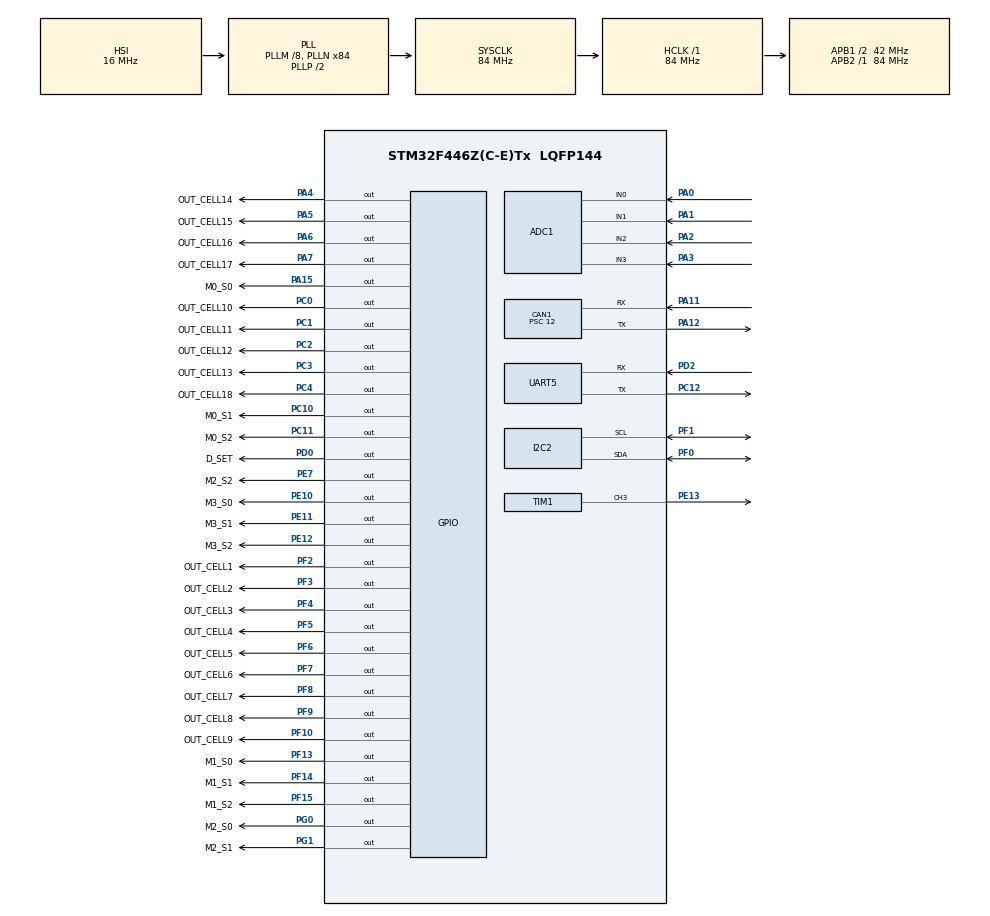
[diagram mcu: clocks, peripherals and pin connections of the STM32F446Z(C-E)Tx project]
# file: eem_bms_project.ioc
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ADC1.Channel-0\#ChannelRegularConversion=ADC_CHANNEL_0
ADC1.Channel-1\#ChannelRegularConversion=ADC_CHANNEL_1
ADC1.Channel-2\#ChannelRegularConversion=ADC_CHANNEL_2
ADC1.Channel-3\#ChannelRegularConversion=ADC_CHANNEL_3
ADC1.Channel-5\#ChannelRegularConversion=ADC_CHANNEL_VBAT
ADC1.Channel-6\#ChannelRegularConversion=ADC_CHANNEL_VREFINT
ADC1.ContinuousConvMode=ENABLE
ADC1.NbrOfConversion=6
ADC1.NbrOfConversionFlag=1
ADC1.Rank-0\#ChannelRegularConversion=1
ADC1.Rank-1\#ChannelRegularConversion=2
ADC1.Rank-2\#ChannelRegularConversion=3
ADC1.Rank-3\#ChannelRegularConversion=4
ADC1.Rank-5\#ChannelRegularConversion=5
ADC1.Rank-6\#ChannelRegularConversion=6
ADC1.SamplingTime-0\#ChannelRegularConversion=ADC_SAMPLETIME_480CYCLES
ADC1.SamplingTime-1\#ChannelRegularConversion=ADC_SAMPLETIME_480CYCLES
ADC1.SamplingTime-2\#ChannelRegularConversion=ADC_SAMPLETIME_480CYCLES
ADC1.SamplingTime-3\#ChannelRegularConversion=ADC_SAMPLETIME_480CYCLES
ADC1.SamplingTime-5\#ChannelRegularConversion=ADC_SAMPLETIME_28CYCLES
ADC1.SamplingTime-6\#ChannelRegularConversion=ADC_SAMPLETIME_28CYCLES
ADC1.ScanConvMode=ENABLE
ADC1.master=1
CAN1.BS1=CAN_BS1_11TQ
CAN1.BS2=CAN_BS2_2TQ
CAN1.CalculateBaudRate=250000
CAN1.CalculateTimeBit=4000
CAN1.CalculateTimeQuantum=285.7142857142857
CAN1.NART=ENABLE
CAN1.Prescaler=12
Mcu.Family=STM32F4
Mcu.Name=STM32F446Z(C-E)Tx
Mcu.Package=LQFP144
NVIC.CAN1_RX0_IRQn=true\:0\:0\:false\:false\:true\:true\:true\:true
NVIC.CAN1_RX1_IRQn=true\:0\:0\:false\:false\:true\:true\:true\:true
NVIC.CAN1_SCE_IRQn=true\:0\:0\:false\:false\:true\:true\:true\:true
NVIC.CAN1_TX_IRQn=true\:0\:0\:false\:false\:true\:true\:true\:true
NVIC.PriorityGroup=NVIC_PRIORITYGROUP_4
PA0-WKUP.Signal=ADCx_IN0
PA1.Signal=ADCx_IN1
PA11.Mode=CAN_Activate
PA11.Signal=CAN1_RX
PA12.Mode=CAN_Activate
PA12.Signal=CAN1_TX
PA13.Mode=Serial_Wire
PA13.Signal=SYS_JTMS-SWDIO
PA14.Mode=Serial_Wire
PA14.Signal=SYS_JTCK-SWCLK
PA15.GPIO_Label=M0_S0
PA15.Signal=GPIO_Output
PA2.Signal=ADCx_IN2
PA3.Signal=ADCx_IN3
PA4.GPIO_Label=OUT_CELL14
PA4.Signal=GPIO_Output
PA5.GPIO_Label=OUT_CELL15
PA5.Signal=GPIO_Output
PA6.GPIO_Label=OUT_CELL16
PA6.Signal=GPIO_Output
PA7.GPIO_Label=OUT_CELL17
PA7.Signal=GPIO_Output
PC0.GPIO_Label=OUT_CELL10
PC0.Signal=GPIO_Output
PC1.GPIO_Label=OUT_CELL11
PC1.Signal=GPIO_Output
PC10.GPIO_Label=M0_S1
PC10.Signal=GPIO_Output
PC11.GPIO_Label=M0_S2
PC11.Signal=GPIO_Output
PC12.Mode=Asynchronous
PC12.Signal=UART5_TX
PC2.GPIO_Label=OUT_CELL12
PC2.Signal=GPIO_Output
PC3.GPIO_Label=OUT_CELL13
PC3.Signal=GPIO_Output
PC4.GPIO_Label=OUT_CELL18
PC4.Signal=GPIO_Output
PD0.GPIO_Label=D_SET
PD0.Signal=GPIO_Output
PD2.Mode=Asynchronous
PD2.Signal=UART5_RX
PE10.GPIO_Label=M3_S0
PE10.Signal=GPIO_Output
PE11.GPIO_Label=M3_S1
PE11.Signal=GPIO_Output
PE12.GPIO_Label=M3_S2
PE12.Signal=GPIO_Output
PE13.Signal=S_TIM1_CH3
PE7.GPIO_Label=M2_S2
PE7.Signal=GPIO_Output
PF0.Mode=I2C
PF0.Signal=I2C2_SDA
PF1.Mode=I2C
PF1.Signal=I2C2_SCL
PF10.GPIO_Label=OUT_CELL9
PF10.Signal=GPIO_Output
PF13.GPIO_Label=M1_S0
PF13.Signal=GPIO_Output
PF14.GPIO_Label=M1_S1
PF14.Signal=GPIO_Output
PF15.GPIO_Label=M1_S2
PF15.Signal=GPIO_Output
PF2.GPIO_Label=OUT_CELL1
PF2.Signal=GPIO_Output
PF3.GPIO_Label=OUT_CELL2
PF3.Signal=GPIO_Output
PF4.GPIO_Label=OUT_CELL3
PF4.Signal=GPIO_Output
PF5.GPIO_Label=OUT_CELL4
PF5.Signal=GPIO_Output
PF6.GPIO_Label=OUT_CELL5
PF6.Signal=GPIO_Output
PF7.GPIO_Label=OUT_CELL6
PF7.Signal=GPIO_Output
PF8.GPIO_Label=OUT_CELL7
PF8.Signal=GPIO_Output
PF9.GPIO_Label=OUT_CELL8
PF9.Signal=GPIO_Output
PG0.GPIO_Label=M2_S0
PG0.Signal=GPIO_Output
PG1.GPIO_Label=M2_S1
PG1.Signal=GPIO_Output
PH0-OSC_IN.Mode=HSE-External-Oscillator
PH0-OSC_IN.Signal=RCC_OSC_IN
PH1-OSC_OUT.Mode=HSE-External-Oscillator
PH1-OSC_OUT.Signal=RCC_OSC_OUT
ProjectManager.HeapSize=0x200
ProjectManager.StackSize=0x400
ProjectManager.TargetToolchain=STM32CubeIDE
RCC.AHBFreq_Value=84000000
RCC.APB1CLKDivider=RCC_HCLK_DIV2
RCC.APB1Freq_Value=42000000
RCC.APB1TimFreq_Value=84000000
RCC.APB2Freq_Value=84000000
RCC.APB2TimFreq_Value=84000000
RCC.CortexFreq_Value=84000000
RCC.HCLKFreq_Value=84000000
RCC.PLLM=8
RCC.PLLN=84
RCC.SYSCLKFreq_VALUE=84000000
RCC.SYSCLKSource=RCC_SYSCLKSOURCE_PLLCLK
RCC.USBFreq_Value=84000000
RCC.VCOOutputFreq_Value=168000000
SH.ADCx_IN0.0=ADC1_IN0,IN0
SH.ADCx_IN1.0=ADC1_IN1,IN1
SH.ADCx_IN2.0=ADC1_IN2,IN2
SH.ADCx_IN3.0=ADC1_IN3,IN3
SH.S_TIM1_CH3.0=TIM1_CH3,Output Compare3 CH3
TIM1.Channel-Output\ Compare3\ CH3=TIM_CHANNEL_3
TIM1.Period=8399
TIM1.Prescaler=5
UART5.VirtualMode=Asynchronous
VP_ADC1_Vbat_Input.Mode=IN-Vbat
VP_ADC1_Vref_Input.Mode=IN-Vrefint
VP_RTC_VS_RTC_Activate.Mode=RTC_Enabled
VP_TIM1_VS_ClockSourceINT.Mode=Internal
board=custom

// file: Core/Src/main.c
/* USER CODE BEGIN Header */
/**
  ******************************************************************************
  * @file           : main.c
  * @brief          : Main program body
  ******************************************************************************
  * @attention
  *
  * Copyright (c) 2023 STMicroelectronics.
  * All rights reserved.
  *
  * This software is licensed under terms that can be found in the LICENSE file
  * in the root directory of this software component.
  * If no LICENSE file comes with this software, it is provided AS-IS.
  *
  ******************************************************************************
  */
/* USER CODE END Header */
#include "main.h"

ADC_HandleTypeDef hadc1;

CAN_HandleTypeDef hcan1;

I2C_HandleTypeDef hi2c2;

RTC_HandleTypeDef hrtc;

TIM_HandleTypeDef htim1;

UART_HandleTypeDef huart5;

void SystemClock_Config(void);
static void MX_GPIO_Init(void);
static void MX_ADC1_Init(void);
static void MX_CAN1_Init(void);
static void MX_I2C2_Init(void);
static void MX_RTC_Init(void);
static void MX_TIM1_Init(void);
static void MX_UART5_Init(void);

int main(void)
{

  /* MCU Configuration--------------------------------------------------------*/

  /* Reset of all peripherals, Initializes the Flash interface and the Systick. */
  HAL_Init();

  /* Configure the system clock */
  SystemClock_Config();

  /* Initialize all configured peripherals */
  MX_GPIO_Init();
  MX_ADC1_Init();
  MX_CAN1_Init();
  MX_I2C2_Init();
  MX_RTC_Init();
  MX_TIM1_Init();
  MX_UART5_Init();
  /* USER CODE BEGIN 2 */

  /* JUMP INTO MAIN BMS CODE */
  App_MAIN();

  /* USER CODE END 2 */

  /* Infinite loop */
  while (1)
  {

  }
}

void SystemClock_Config(void)
{
  RCC_OscInitTypeDef RCC_OscInitStruct = {0};
  RCC_ClkInitTypeDef RCC_ClkInitStruct = {0};

  /** Configure the main internal regulator output voltage
  */
  __HAL_RCC_PWR_CLK_ENABLE();
  __HAL_PWR_VOLTAGESCALING_CONFIG(PWR_REGULATOR_VOLTAGE_SCALE3);

  /** Initializes the RCC Oscillators according to the specified parameters
  * in the RCC_OscInitTypeDef structure.
  */
  RCC_OscInitStruct.OscillatorType = RCC_OSCILLATORTYPE_HSI|RCC_OSCILLATORTYPE_LSI;
  RCC_OscInitStruct.LSEState = RCC_LSE_OFF;
  RCC_OscInitStruct.HSIState = RCC_HSI_ON;
  RCC_OscInitStruct.HSICalibrationValue = RCC_HSICALIBRATION_DEFAULT;
  RCC_OscInitStruct.LSIState = RCC_LSI_ON;
  RCC_OscInitStruct.PLL.PLLState = RCC_PLL_ON;
  RCC_OscInitStruct.PLL.PLLSource = RCC_PLLSOURCE_HSI;
  RCC_OscInitStruct.PLL.PLLM = 8;
  RCC_OscInitStruct.PLL.PLLN = 84;
  RCC_OscInitStruct.PLL.PLLP = RCC_PLLP_DIV2;
  RCC_OscInitStruct.PLL.PLLQ = 2;
  RCC_OscInitStruct.PLL.PLLR = 2;
  if (HAL_RCC_OscConfig(&RCC_OscInitStruct) != HAL_OK)
  {
    Error_Handler();
  }

  /** Initializes the CPU, AHB and APB buses clocks
  */
  RCC_ClkInitStruct.ClockType = RCC_CLOCKTYPE_HCLK|RCC_CLOCKTYPE_SYSCLK
                              |RCC_CLOCKTYPE_PCLK1|RCC_CLOCKTYPE_PCLK2;
  RCC_ClkInitStruct.SYSCLKSource = RCC_SYSCLKSOURCE_PLLCLK;
  RCC_ClkInitStruct.AHBCLKDivider = RCC_SYSCLK_DIV1;
  RCC_ClkInitStruct.APB1CLKDivider = RCC_HCLK_DIV2;
  RCC_ClkInitStruct.APB2CLKDivider = RCC_HCLK_DIV1;

  if (HAL_RCC_ClockConfig(&RCC_ClkInitStruct, FLASH_LATENCY_2) != HAL_OK)
  {
    Error_Handler();
  }
}

static void MX_ADC1_Init(void)
{

  ADC_ChannelConfTypeDef sConfig = {0};

  /** Configure the global features of the ADC (Clock, Resolution, Data Alignment and number of conversion)
  */
  hadc1.Instance = ADC1;
  hadc1.Init.ClockPrescaler = ADC_CLOCK_SYNC_PCLK_DIV4;
  hadc1.Init.Resolution = ADC_RESOLUTION_12B;
  hadc1.Init.ScanConvMode = ENABLE;
  hadc1.Init.ContinuousConvMode = ENABLE;
  hadc1.Init.DiscontinuousConvMode = DISABLE;
  hadc1.Init.ExternalTrigConvEdge = ADC_EXTERNALTRIGCONVEDGE_NONE;
  hadc1.Init.ExternalTrigConv = ADC_SOFTWARE_START;
  hadc1.Init.DataAlign = ADC_DATAALIGN_RIGHT;
  hadc1.Init.NbrOfConversion = 6;
  hadc1.Init.DMAContinuousRequests = DISABLE;
  hadc1.Init.EOCSelection = ADC_EOC_SINGLE_CONV;
  if (HAL_ADC_Init(&hadc1) != HAL_OK)
  {
    Error_Handler();
  }

  /** Configure for the selected ADC regular channel its corresponding rank in the sequencer and its sample time.
  */
  sConfig.Channel = ADC_CHANNEL_0;
  sConfig.Rank = 1;
  sConfig.SamplingTime = ADC_SAMPLETIME_480CYCLES;
  if (HAL_ADC_ConfigChannel(&hadc1, &sConfig) != HAL_OK)
  {
    Error_Handler();
  }

  /** Configure for the selected ADC regular channel its corresponding rank in the sequencer and its sample time.
  */
  sConfig.Channel = ADC_CHANNEL_1;
  sConfig.Rank = 2;
  if (HAL_ADC_ConfigChannel(&hadc1, &sConfig) != HAL_OK)
  {
    Error_Handler();
  }

  /** Configure for the selected ADC regular channel its corresponding rank in the sequencer and its sample time.
  */
  sConfig.Channel = ADC_CHANNEL_2;
  sConfig.Rank = 3;
  if (HAL_ADC_ConfigChannel(&hadc1, &sConfig) != HAL_OK)
  {
    Error_Handler();
  }

  /** Configure for the selected ADC regular channel its corresponding rank in the sequencer and its sample time.
  */
  sConfig.Channel = ADC_CHANNEL_3;
  sConfig.Rank = 4;
  if (HAL_ADC_ConfigChannel(&hadc1, &sConfig) != HAL_OK)
  {
    Error_Handler();
  }

  /** Configure for the selected ADC regular channel its corresponding rank in the sequencer and its sample time.
  */
  sConfig.Channel = ADC_CHANNEL_VBAT;
  sConfig.Rank = 5;
  sConfig.SamplingTime = ADC_SAMPLETIME_28CYCLES;
  if (HAL_ADC_ConfigChannel(&hadc1, &sConfig) != HAL_OK)
  {
    Error_Handler();
  }

  /** Configure for the selected ADC regular channel its corresponding rank in the sequencer and its sample time.
  */
  sConfig.Channel = ADC_CHANNEL_VREFINT;
  sConfig.Rank = 6;
  if (HAL_ADC_ConfigChannel(&hadc1, &sConfig) != HAL_OK)
  {
    Error_Handler();
  }

}

static void MX_CAN1_Init(void)
{

  hcan1.Instance = CAN1;
  hcan1.Init.Prescaler = 12;
  hcan1.Init.Mode = CAN_MODE_NORMAL;
  hcan1.Init.SyncJumpWidth = CAN_SJW_1TQ;
  hcan1.Init.TimeSeg1 = CAN_BS1_11TQ;
  hcan1.Init.TimeSeg2 = CAN_BS2_2TQ;
  hcan1.Init.TimeTriggeredMode = DISABLE;
  hcan1.Init.AutoBusOff = DISABLE;
  hcan1.Init.AutoWakeUp = DISABLE;
  hcan1.Init.AutoRetransmission = ENABLE;
  hcan1.Init.ReceiveFifoLocked = DISABLE;
  hcan1.Init.TransmitFifoPriority = DISABLE;
  if (HAL_CAN_Init(&hcan1) != HAL_OK)
  {
    Error_Handler();
  }

}

static void MX_I2C2_Init(void)
{

  hi2c2.Instance = I2C2;
  hi2c2.Init.ClockSpeed = 100000;
  hi2c2.Init.DutyCycle = I2C_DUTYCYCLE_2;
  hi2c2.Init.OwnAddress1 = 0;
  hi2c2.Init.AddressingMode = I2C_ADDRESSINGMODE_7BIT;
  hi2c2.Init.DualAddressMode = I2C_DUALADDRESS_DISABLE;
  hi2c2.Init.OwnAddress2 = 0;
  hi2c2.Init.GeneralCallMode = I2C_GENERALCALL_DISABLE;
  hi2c2.Init.NoStretchMode = I2C_NOSTRETCH_DISABLE;
  if (HAL_I2C_Init(&hi2c2) != HAL_OK)
  {
    Error_Handler();
  }

}

static void MX_RTC_Init(void)
{

  /** Initialize RTC Only
  */
  hrtc.Instance = RTC;
  hrtc.Init.HourFormat = RTC_HOURFORMAT_24;
  hrtc.Init.AsynchPrediv = 127;
  hrtc.Init.SynchPrediv = 255;
  hrtc.Init.OutPut = RTC_OUTPUT_DISABLE;
  hrtc.Init.OutPutPolarity = RTC_OUTPUT_POLARITY_HIGH;
  hrtc.Init.OutPutType = RTC_OUTPUT_TYPE_OPENDRAIN;
  if (HAL_RTC_Init(&hrtc) != HAL_OK)
  {
    Error_Handler();
  }

}

static void MX_TIM1_Init(void)
{

  TIM_ClockConfigTypeDef sClockSourceConfig = {0};
  TIM_MasterConfigTypeDef sMasterConfig = {0};
  TIM_OC_InitTypeDef sConfigOC = {0};
  TIM_BreakDeadTimeConfigTypeDef sBreakDeadTimeConfig = {0};

  htim1.Instance = TIM1;
  htim1.Init.Prescaler = 5;
  htim1.Init.CounterMode = TIM_COUNTERMODE_UP;
  htim1.Init.Period = 8399;
  htim1.Init.ClockDivision = TIM_CLOCKDIVISION_DIV1;
  htim1.Init.RepetitionCounter = 0;
  htim1.Init.AutoReloadPreload = TIM_AUTORELOAD_PRELOAD_DISABLE;
  if (HAL_TIM_Base_Init(&htim1) != HAL_OK)
  {
    Error_Handler();
  }
  sClockSourceConfig.ClockSource = TIM_CLOCKSOURCE_INTERNAL;
  if (HAL_TIM_ConfigClockSource(&htim1, &sClockSourceConfig) != HAL_OK)
  {
    Error_Handler();
  }
  if (HAL_TIM_OC_Init(&htim1) != HAL_OK)
  {
    Error_Handler();
  }
  sMasterConfig.MasterOutputTrigger = TIM_TRGO_RESET;
  sMasterConfig.MasterSlaveMode = TIM_MASTERSLAVEMODE_DISABLE;
  if (HAL_TIMEx_MasterConfigSynchronization(&htim1, &sMasterConfig) != HAL_OK)
  {
    Error_Handler();
  }
  sConfigOC.OCMode = TIM_OCMODE_TIMING;
  sConfigOC.Pulse = 0;
  sConfigOC.OCPolarity = TIM_OCPOLARITY_HIGH;
  sConfigOC.OCNPolarity = TIM_OCNPOLARITY_HIGH;
  sConfigOC.OCFastMode = TIM_OCFAST_DISABLE;
  sConfigOC.OCIdleState = TIM_OCIDLESTATE_RESET;
  sConfigOC.OCNIdleState = TIM_OCNIDLESTATE_RESET;
  if (HAL_TIM_OC_ConfigChannel(&htim1, &sConfigOC, TIM_CHANNEL_3) != HAL_OK)
  {
    Error_Handler();
  }
  sBreakDeadTimeConfig.OffStateRunMode = TIM_OSSR_DISABLE;
  sBreakDeadTimeConfig.OffStateIDLEMode = TIM_OSSI_DISABLE;
  sBreakDeadTimeConfig.LockLevel = TIM_LOCKLEVEL_OFF;
  sBreakDeadTimeConfig.DeadTime = 0;
  sBreakDeadTimeConfig.BreakState = TIM_BREAK_DISABLE;
  sBreakDeadTimeConfig.BreakPolarity = TIM_BREAKPOLARITY_HIGH;
  sBreakDeadTimeConfig.AutomaticOutput = TIM_AUTOMATICOUTPUT_DISABLE;
  if (HAL_TIMEx_ConfigBreakDeadTime(&htim1, &sBreakDeadTimeConfig) != HAL_OK)
  {
    Error_Handler();
  }
  HAL_TIM_MspPostInit(&htim1);

}

static void MX_UART5_Init(void)
{

  huart5.Instance = UART5;
  huart5.Init.BaudRate = 115200;
  huart5.Init.WordLength = UART_WORDLENGTH_8B;
  huart5.Init.StopBits = UART_STOPBITS_1;
  huart5.Init.Parity = UART_PARITY_NONE;
  huart5.Init.Mode = UART_MODE_TX_RX;
  huart5.Init.HwFlowCtl = UART_HWCONTROL_NONE;
  huart5.Init.OverSampling = UART_OVERSAMPLING_16;
  if (HAL_UART_Init(&huart5) != HAL_OK)
  {
    Error_Handler();
  }

}

static void MX_GPIO_Init(void)
{
  GPIO_InitTypeDef GPIO_InitStruct = {0};

  /* GPIO Ports Clock Enable */
  __HAL_RCC_GPIOF_CLK_ENABLE();
  __HAL_RCC_GPIOH_CLK_ENABLE();
  __HAL_RCC_GPIOC_CLK_ENABLE();
  __HAL_RCC_GPIOA_CLK_ENABLE();
  __HAL_RCC_GPIOG_CLK_ENABLE();
  __HAL_RCC_GPIOE_CLK_ENABLE();
  __HAL_RCC_GPIOD_CLK_ENABLE();

  /*Configure GPIO pin Output Level */
  HAL_GPIO_WritePin(GPIOF, OUT_CELL1_Pin|OUT_CELL2_Pin|OUT_CELL3_Pin|OUT_CELL4_Pin
                          |OUT_CELL5_Pin|OUT_CELL6_Pin|OUT_CELL7_Pin|OUT_CELL8_Pin
                          |OUT_CELL9_Pin|M1_S0_Pin|M1_S1_Pin|M1_S2_Pin, GPIO_PIN_RESET);

  /*Configure GPIO pin Output Level */
  HAL_GPIO_WritePin(GPIOC, OUT_CELL10_Pin|OUT_CELL11_Pin|OUT_CELL12_Pin|OUT_CELL13_Pin
                          |OUT_CELL18_Pin|M0_S1_Pin|M0_S2_Pin, GPIO_PIN_RESET);

  /*Configure GPIO pin Output Level */
  HAL_GPIO_WritePin(GPIOA, OUT_CELL14_Pin|OUT_CELL15_Pin|OUT_CELL16_Pin|OUT_CELL17_Pin
                          |M0_S0_Pin, GPIO_PIN_RESET);

  /*Configure GPIO pin Output Level */
  HAL_GPIO_WritePin(GPIOG, M2_S0_Pin|M2_S1_Pin, GPIO_PIN_RESET);

  /*Configure GPIO pin Output Level */
  HAL_GPIO_WritePin(GPIOE, M2_S2_Pin|M3_S0_Pin|M3_S1_Pin|M3_S2_Pin, GPIO_PIN_RESET);

  /*Configure GPIO pin Output Level */
  HAL_GPIO_WritePin(D_SET_GPIO_Port, D_SET_Pin, GPIO_PIN_RESET);

  /*Configure GPIO pins : OUT_CELL1_Pin OUT_CELL2_Pin OUT_CELL3_Pin OUT_CELL4_Pin
                           OUT_CELL5_Pin OUT_CELL6_Pin OUT_CELL7_Pin OUT_CELL8_Pin
                           OUT_CELL9_Pin M1_S0_Pin M1_S1_Pin M1_S2_Pin */
  GPIO_InitStruct.Pin = OUT_CELL1_Pin|OUT_CELL2_Pin|OUT_CELL3_Pin|OUT_CELL4_Pin
                          |OUT_CELL5_Pin|OUT_CELL6_Pin|OUT_CELL7_Pin|OUT_CELL8_Pin
                          |OUT_CELL9_Pin|M1_S0_Pin|M1_S1_Pin|M1_S2_Pin;
  GPIO_InitStruct.Mode = GPIO_MODE_OUTPUT_PP;
  GPIO_InitStruct.Pull = GPIO_NOPULL;
  GPIO_InitStruct.Speed = GPIO_SPEED_FREQ_LOW;
  HAL_GPIO_Init(GPIOF, &GPIO_InitStruct);

  /*Configure GPIO pins : OUT_CELL10_Pin OUT_CELL11_Pin OUT_CELL12_Pin OUT_CELL13_Pin
                           OUT_CELL18_Pin M0_S1_Pin M0_S2_Pin */
  GPIO_InitStruct.Pin = OUT_CELL10_Pin|OUT_CELL11_Pin|OUT_CELL12_Pin|OUT_CELL13_Pin
                          |OUT_CELL18_Pin|M0_S1_Pin|M0_S2_Pin;
  GPIO_InitStruct.Mode = GPIO_MODE_OUTPUT_PP;
  GPIO_InitStruct.Pull = GPIO_NOPULL;
  GPIO_InitStruct.Speed = GPIO_SPEED_FREQ_LOW;
  HAL_GPIO_Init(GPIOC, &GPIO_InitStruct);

  /*Configure GPIO pins : OUT_CELL14_Pin OUT_CELL15_Pin OUT_CELL16_Pin OUT_CELL17_Pin
                           M0_S0_Pin */
  GPIO_InitStruct.Pin = OUT_CELL14_Pin|OUT_CELL15_Pin|OUT_CELL16_Pin|OUT_CELL17_Pin
                          |M0_S0_Pin;
  GPIO_InitStruct.Mode = GPIO_MODE_OUTPUT_PP;
  GPIO_InitStruct.Pull = GPIO_NOPULL;
  GPIO_InitStruct.Speed = GPIO_SPEED_FREQ_LOW;
  HAL_GPIO_Init(GPIOA, &GPIO_InitStruct);

  /*Configure GPIO pins : M2_S0_Pin M2_S1_Pin */
  GPIO_InitStruct.Pin = M2_S0_Pin|M2_S1_Pin;
  GPIO_InitStruct.Mode = GPIO_MODE_OUTPUT_PP;
  GPIO_InitStruct.Pull = GPIO_NOPULL;
  GPIO_InitStruct.Speed = GPIO_SPEED_FREQ_LOW;
  HAL_GPIO_Init(GPIOG, &GPIO_InitStruct);

  /*Configure GPIO pins : M2_S2_Pin M3_S0_Pin M3_S1_Pin M3_S2_Pin */
  GPIO_InitStruct.Pin = M2_S2_Pin|M3_S0_Pin|M3_S1_Pin|M3_S2_Pin;
  GPIO_InitStruct.Mode = GPIO_MODE_OUTPUT_PP;
  GPIO_InitStruct.Pull = GPIO_NOPULL;
  GPIO_InitStruct.Speed = GPIO_SPEED_FREQ_LOW;
  HAL_GPIO_Init(GPIOE, &GPIO_InitStruct);

  /*Configure GPIO pin : D_SET_Pin */
  GPIO_InitStruct.Pin = D_SET_Pin;
  GPIO_InitStruct.Mode = GPIO_MODE_OUTPUT_PP;
  GPIO_InitStruct.Pull = GPIO_NOPULL;
  GPIO_InitStruct.Speed = GPIO_SPEED_FREQ_LOW;
  HAL_GPIO_Init(D_SET_GPIO_Port, &GPIO_InitStruct);

}

void Error_Handler(void)
{
  __disable_irq();
  while (1)
  {
  }
}
